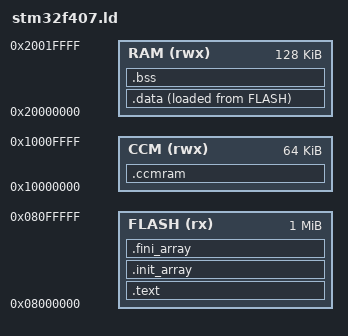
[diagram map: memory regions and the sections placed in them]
/* ===========================================================================
 *  Linker script for STM32F407VG (Cortex-M4F)
 *    1 MB FLASH @ 0x08000000, 128 KB SRAM @ 0x20000000 (+ 64 KB CCM)
 * =========================================================================== */

ENTRY(Reset_Handler)

MEMORY
{
    FLASH (rx)  : ORIGIN = 0x08000000, LENGTH = 1024K
    RAM   (rwx) : ORIGIN = 0x20000000, LENGTH = 128K
    CCM   (rwx) : ORIGIN = 0x10000000, LENGTH = 64K
}

/* Top of stack = end of main RAM. */
_estack = ORIGIN(RAM) + LENGTH(RAM);

SECTIONS
{
    /* Vector table first, then code and read-only data, in FLASH. */
    .text :
    {
        . = ALIGN(4);
        KEEP(*(.isr_vector))
        *(.text)
        *(.text*)
        *(.rodata)
        *(.rodata*)
        . = ALIGN(4);
    } > FLASH

    /* C++ static constructor / destructor arrays. */
    .init_array :
    {
        . = ALIGN(4);
        __init_array_start = .;
        KEEP(*(SORT(.init_array.*)))
        KEEP(*(.init_array))
        __init_array_end = .;
        . = ALIGN(4);
    } > FLASH

    .fini_array :
    {
        . = ALIGN(4);
        KEEP(*(.fini_array))
        KEEP(*(SORT(.fini_array.*)))
        . = ALIGN(4);
    } > FLASH

    /* Load address of .data in FLASH. */
    _sidata = LOADADDR(.data);

    /* Initialized data: resides in RAM, loaded from FLASH at startup. */
    .data :
    {
        . = ALIGN(4);
        _sdata = .;
        *(.data)
        *(.data*)
        . = ALIGN(4);
        _edata = .;
    } > RAM AT > FLASH

    /* Zero-initialized data. */
    .bss :
    {
        . = ALIGN(4);
        _sbss = .;
        *(.bss)
        *(.bss*)
        *(COMMON)
        . = ALIGN(4);
        _ebss = .;
    } > RAM

    /* CCM RAM (optional, not loaded). */
    .ccmram (NOLOAD) :
    {
        . = ALIGN(4);
        *(.ccmram)
        *(.ccmram*)
        . = ALIGN(4);
    } > CCM
}
